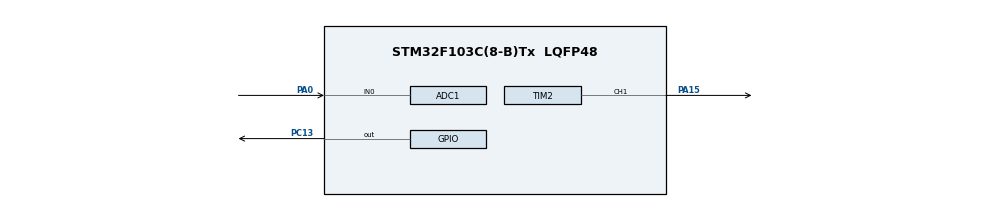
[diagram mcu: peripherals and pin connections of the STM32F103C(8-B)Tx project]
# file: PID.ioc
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ADC1.Channel-0\#ChannelRegularConversion=ADC_CHANNEL_0
ADC1.ContinuousConvMode=ENABLE
ADC1.NbrOfConversionFlag=1
ADC1.Rank-0\#ChannelRegularConversion=1
ADC1.SamplingTime-0\#ChannelRegularConversion=ADC_SAMPLETIME_1CYCLE_5
ADC1.master=1
Mcu.Family=STM32F1
Mcu.Name=STM32F103C(8-B)Tx
Mcu.Package=LQFP48
NVIC.PriorityGroup=NVIC_PRIORITYGROUP_4
NVIC.TIM3_IRQn=true\:0\:0\:false\:false\:true\:true
PA0-WKUP.Signal=ADCx_IN0
PA13.Mode=Serial_Wire
PA13.Signal=SYS_JTMS-SWDIO
PA14.Mode=Serial_Wire
PA14.Signal=SYS_JTCK-SWCLK
PA15.Signal=S_TIM2_CH1_ETR
PC13-TAMPER-RTC.Signal=GPIO_Output
PD0-OSC_IN.Mode=HSE-External-Oscillator
PD0-OSC_IN.Signal=RCC_OSC_IN
PD1-OSC_OUT.Mode=HSE-External-Oscillator
PD1-OSC_OUT.Signal=RCC_OSC_OUT
ProjectManager.HeapSize=0x200
ProjectManager.StackSize=0x400
ProjectManager.TargetToolchain=MDK-ARM V5
RCC.APB1Freq_Value=8000000
RCC.APB2Freq_Value=8000000
SH.ADCx_IN0.0=ADC1_IN0,IN0
SH.S_TIM2_CH1_ETR.0=TIM2_CH1,PWM Generation1 CH1
TIM2.Channel-PWM\ Generation1\ CH1=TIM_CHANNEL_1
TIM2.Period=65535
TIM3.Period=500-1
TIM3.Prescaler=8000-1
VP_TIM2_VS_ClockSourceINT.Mode=Internal
VP_TIM3_VS_ClockSourceINT.Mode=Internal
board=custom

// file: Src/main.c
/**
  ******************************************************************************
  * @file           : main.c
  * @brief          : Main program body
  ******************************************************************************
  ** This notice applies to any and all portions of this file
  * that are not between comment pairs USER CODE BEGIN and
  * USER CODE END. Other portions of this file, whether
  * inserted by the user or by software development tools
  * are owned by their respective copyright owners.
  *
  * COPYRIGHT(c) 2018 STMicroelectronics
  *
  * Redistribution and use in source and binary forms, with or without modification,
  * are permitted provided that the following conditions are met:
  *   1. Redistributions of source code must retain the above copyright notice,
  *      this list of conditions and the following disclaimer.
  *   2. Redistributions in binary form must reproduce the above copyright notice,
  *      this list of conditions and the following disclaimer in the documentation
  *      and/or other materials provided with the distribution.
  *   3. Neither the name of STMicroelectronics nor the names of its contributors
  *      may be used to endorse or promote products derived from this software
  *      without specific prior written permission.
  *
  * THIS SOFTWARE IS PROVIDED BY THE COPYRIGHT HOLDERS AND CONTRIBUTORS "AS IS"
  * AND ANY EXPRESS OR IMPLIED WARRANTIES, INCLUDING, BUT NOT LIMITED TO, THE
  * IMPLIED WARRANTIES OF MERCHANTABILITY AND FITNESS FOR A PARTICULAR PURPOSE ARE
  * DISCLAIMED. IN NO EVENT SHALL THE COPYRIGHT HOLDER OR CONTRIBUTORS BE LIABLE
  * FOR ANY DIRECT, INDIRECT, INCIDENTAL, SPECIAL, EXEMPLARY, OR CONSEQUENTIAL
  * DAMAGES (INCLUDING, BUT NOT LIMITED TO, PROCUREMENT OF SUBSTITUTE GOODS OR
  * SERVICES; LOSS OF USE, DATA, OR PROFITS; OR BUSINESS INTERRUPTION) HOWEVER
  * CAUSED AND ON ANY THEORY OF LIABILITY, WHETHER IN CONTRACT, STRICT LIABILITY,
  * OR TORT (INCLUDING NEGLIGENCE OR OTHERWISE) ARISING IN ANY WAY OUT OF THE USE
  * OF THIS SOFTWARE, EVEN IF ADVISED OF THE POSSIBILITY OF SUCH DAMAGE.
  *
  ******************************************************************************
  */
#include "main.h"
#include "stm32f1xx_hal.h"

/* USER CODE BEGIN Includes */
#include "pid_controller.h"
/* USER CODE END Includes */

ADC_HandleTypeDef hadc1;

TIM_HandleTypeDef htim2;
TIM_HandleTypeDef htim3;

/* USER CODE BEGIN PV */
/* Private variables ---------------------------------------------------------*/

/* USER CODE END PV */

void SystemClock_Config(void);
static void MX_GPIO_Init(void);
static void MX_TIM2_Init(void);
static void MX_TIM3_Init(void);
static void MX_ADC1_Init(void);

void HAL_TIM_MspPostInit(TIM_HandleTypeDef *htim);

/* USER CODE BEGIN PFP */
/* Private function prototypes -----------------------------------------------*/
PIDControl pid;
int temp, i;
/* USER CODE END PFP */

/* USER CODE BEGIN 0 */
void HAL_TIM_PeriodElapsedCallback(TIM_HandleTypeDef *htim)
{
		HAL_GPIO_TogglePin(GPIOC, GPIO_PIN_13);
		PIDCompute(&pid);
}
/* USER CODE END 0 */

int main(void)
{

  /* MCU Configuration----------------------------------------------------------*/

  /* Reset of all peripherals, Initializes the Flash interface and the Systick. */
  HAL_Init();

  /* Configure the system clock */
  SystemClock_Config();

  /* Initialize all configured peripherals */
  MX_GPIO_Init();
  MX_TIM2_Init();
  MX_TIM3_Init();
  MX_ADC1_Init();
  /* USER CODE BEGIN 2 */
	PIDInit(&pid, 2, 5, 1, 0, 0, 255, AUTOMATIC, DIRECT);
	pid.setpoint = 40;
	HAL_ADC_Start(&hadc1);
	HAL_TIM_Base_Start_IT(&htim3);
  /* USER CODE END 2 */

  /* Infinite loop */
  while (1)
  {

  /* USER CODE BEGIN 3 */
		for(i=0;i<50;i++)
			temp += (HAL_ADC_GetValue(&hadc1)*3.3)/4096*100-6;
		temp/=50;
		printf("%d ", temp);
		pid.input = temp;
		printf("Output: %f\n", pid.output);
		HAL_Delay(100);
  }
  /* USER CODE END 3 */

}

void SystemClock_Config(void)
{

  RCC_OscInitTypeDef RCC_OscInitStruct;
  RCC_ClkInitTypeDef RCC_ClkInitStruct;
  RCC_PeriphCLKInitTypeDef PeriphClkInit;

    /**Initializes the CPU, AHB and APB busses clocks
    */
  RCC_OscInitStruct.OscillatorType = RCC_OSCILLATORTYPE_HSI;
  RCC_OscInitStruct.HSIState = RCC_HSI_ON;
  RCC_OscInitStruct.HSICalibrationValue = 16;
  RCC_OscInitStruct.PLL.PLLState = RCC_PLL_NONE;
  if (HAL_RCC_OscConfig(&RCC_OscInitStruct) != HAL_OK)
  {
    _Error_Handler(__FILE__, __LINE__);
  }

    /**Initializes the CPU, AHB and APB busses clocks
    */
  RCC_ClkInitStruct.ClockType = RCC_CLOCKTYPE_HCLK|RCC_CLOCKTYPE_SYSCLK
                              |RCC_CLOCKTYPE_PCLK1|RCC_CLOCKTYPE_PCLK2;
  RCC_ClkInitStruct.SYSCLKSource = RCC_SYSCLKSOURCE_HSI;
  RCC_ClkInitStruct.AHBCLKDivider = RCC_SYSCLK_DIV1;
  RCC_ClkInitStruct.APB1CLKDivider = RCC_HCLK_DIV1;
  RCC_ClkInitStruct.APB2CLKDivider = RCC_HCLK_DIV1;

  if (HAL_RCC_ClockConfig(&RCC_ClkInitStruct, FLASH_LATENCY_0) != HAL_OK)
  {
    _Error_Handler(__FILE__, __LINE__);
  }

  PeriphClkInit.PeriphClockSelection = RCC_PERIPHCLK_ADC;
  PeriphClkInit.AdcClockSelection = RCC_ADCPCLK2_DIV2;
  if (HAL_RCCEx_PeriphCLKConfig(&PeriphClkInit) != HAL_OK)
  {
    _Error_Handler(__FILE__, __LINE__);
  }

    /**Configure the Systick interrupt time
    */
  HAL_SYSTICK_Config(HAL_RCC_GetHCLKFreq()/1000);

    /**Configure the Systick
    */
  HAL_SYSTICK_CLKSourceConfig(SYSTICK_CLKSOURCE_HCLK);

  /* SysTick_IRQn interrupt configuration */
  HAL_NVIC_SetPriority(SysTick_IRQn, 0, 0);
}

/* ADC1 init function */
static void MX_ADC1_Init(void)
{

  ADC_ChannelConfTypeDef sConfig;

    /**Common config
    */
  hadc1.Instance = ADC1;
  hadc1.Init.ScanConvMode = ADC_SCAN_DISABLE;
  hadc1.Init.ContinuousConvMode = ENABLE;
  hadc1.Init.DiscontinuousConvMode = DISABLE;
  hadc1.Init.ExternalTrigConv = ADC_SOFTWARE_START;
  hadc1.Init.DataAlign = ADC_DATAALIGN_RIGHT;
  hadc1.Init.NbrOfConversion = 1;
  if (HAL_ADC_Init(&hadc1) != HAL_OK)
  {
    _Error_Handler(__FILE__, __LINE__);
  }

    /**Configure Regular Channel
    */
  sConfig.Channel = ADC_CHANNEL_0;
  sConfig.Rank = ADC_REGULAR_RANK_1;
  sConfig.SamplingTime = ADC_SAMPLETIME_1CYCLE_5;
  if (HAL_ADC_ConfigChannel(&hadc1, &sConfig) != HAL_OK)
  {
    _Error_Handler(__FILE__, __LINE__);
  }

}

/* TIM2 init function */
static void MX_TIM2_Init(void)
{

  TIM_ClockConfigTypeDef sClockSourceConfig;
  TIM_MasterConfigTypeDef sMasterConfig;
  TIM_OC_InitTypeDef sConfigOC;

  htim2.Instance = TIM2;
  htim2.Init.Prescaler = 0;
  htim2.Init.CounterMode = TIM_COUNTERMODE_UP;
  htim2.Init.Period = 65535;
  htim2.Init.ClockDivision = TIM_CLOCKDIVISION_DIV1;
  htim2.Init.AutoReloadPreload = TIM_AUTORELOAD_PRELOAD_DISABLE;
  if (HAL_TIM_Base_Init(&htim2) != HAL_OK)
  {
    _Error_Handler(__FILE__, __LINE__);
  }

  sClockSourceConfig.ClockSource = TIM_CLOCKSOURCE_INTERNAL;
  if (HAL_TIM_ConfigClockSource(&htim2, &sClockSourceConfig) != HAL_OK)
  {
    _Error_Handler(__FILE__, __LINE__);
  }

  if (HAL_TIM_PWM_Init(&htim2) != HAL_OK)
  {
    _Error_Handler(__FILE__, __LINE__);
  }

  sMasterConfig.MasterOutputTrigger = TIM_TRGO_RESET;
  sMasterConfig.MasterSlaveMode = TIM_MASTERSLAVEMODE_DISABLE;
  if (HAL_TIMEx_MasterConfigSynchronization(&htim2, &sMasterConfig) != HAL_OK)
  {
    _Error_Handler(__FILE__, __LINE__);
  }

  sConfigOC.OCMode = TIM_OCMODE_PWM1;
  sConfigOC.Pulse = 0;
  sConfigOC.OCPolarity = TIM_OCPOLARITY_HIGH;
  sConfigOC.OCFastMode = TIM_OCFAST_DISABLE;
  if (HAL_TIM_PWM_ConfigChannel(&htim2, &sConfigOC, TIM_CHANNEL_1) != HAL_OK)
  {
    _Error_Handler(__FILE__, __LINE__);
  }

  HAL_TIM_MspPostInit(&htim2);

}

/* TIM3 init function */
static void MX_TIM3_Init(void)
{

  TIM_ClockConfigTypeDef sClockSourceConfig;
  TIM_MasterConfigTypeDef sMasterConfig;

  htim3.Instance = TIM3;
  htim3.Init.Prescaler = 8000-1;
  htim3.Init.CounterMode = TIM_COUNTERMODE_UP;
  htim3.Init.Period = 100-1;
  htim3.Init.ClockDivision = TIM_CLOCKDIVISION_DIV1;
  htim3.Init.AutoReloadPreload = TIM_AUTORELOAD_PRELOAD_DISABLE;
  if (HAL_TIM_Base_Init(&htim3) != HAL_OK)
  {
    _Error_Handler(__FILE__, __LINE__);
  }

  sClockSourceConfig.ClockSource = TIM_CLOCKSOURCE_INTERNAL;
  if (HAL_TIM_ConfigClockSource(&htim3, &sClockSourceConfig) != HAL_OK)
  {
    _Error_Handler(__FILE__, __LINE__);
  }

  sMasterConfig.MasterOutputTrigger = TIM_TRGO_RESET;
  sMasterConfig.MasterSlaveMode = TIM_MASTERSLAVEMODE_DISABLE;
  if (HAL_TIMEx_MasterConfigSynchronization(&htim3, &sMasterConfig) != HAL_OK)
  {
    _Error_Handler(__FILE__, __LINE__);
  }

}

/** Configure pins as
        * Analog
        * Input
        * Output
        * EVENT_OUT
        * EXTI
*/
static void MX_GPIO_Init(void)
{

  GPIO_InitTypeDef GPIO_InitStruct;

  /* GPIO Ports Clock Enable */
  __HAL_RCC_GPIOC_CLK_ENABLE();
  __HAL_RCC_GPIOD_CLK_ENABLE();
  __HAL_RCC_GPIOA_CLK_ENABLE();

  /*Configure GPIO pin Output Level */
  HAL_GPIO_WritePin(GPIOC, GPIO_PIN_13, GPIO_PIN_RESET);

  /*Configure GPIO pin : PC13 */
  GPIO_InitStruct.Pin = GPIO_PIN_13;
  GPIO_InitStruct.Mode = GPIO_MODE_OUTPUT_PP;
  GPIO_InitStruct.Pull = GPIO_NOPULL;
  GPIO_InitStruct.Speed = GPIO_SPEED_FREQ_LOW;
  HAL_GPIO_Init(GPIOC, &GPIO_InitStruct);

}

void _Error_Handler(char *file, int line)
{
  while(1)
  {
  }
}

/************************ (C) COPYRIGHT STMicroelectronics *****END OF FILE****/
